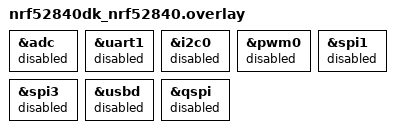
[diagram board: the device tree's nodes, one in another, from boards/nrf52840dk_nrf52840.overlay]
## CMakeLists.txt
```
cmake_minimum_required(VERSION 3.20.0)

find_package(Zephyr HINTS $ENV{ZEPHYR_BASE})
project(matter_nrf52840_thread)

include(${ZEPHYR_CONNECTEDHOMEIP_MODULE_DIR}/config/nrfconnect/app/enable-gnu-std.cmake)
include(${ZEPHYR_NRF_MODULE_DIR}/samples/matter/common/cmake/source_common.cmake)
include(${ZEPHYR_NRF_MODULE_DIR}/samples/matter/common/cmake/data_model.cmake)
include(${ZEPHYR_NRF_MODULE_DIR}/samples/matter/common/cmake/zap_helpers.cmake)
ncs_get_zap_parent_dir(ZAP_PARENT_DIR)

target_include_directories(app PRIVATE
    src
    include
    ${ZAP_PARENT_DIR}
)

target_sources(app PRIVATE
    src/main.cpp
    src/app_task.cpp
    src/dynamic/DynamicEndpointManager.cpp
    src/dynamic/DynamicExports.c
    src/llext/ExtensionLoaderCluster.cpp
    src/llext/ExtensionStore.cpp
)

ncs_configure_data_model()

# LLEXT's table of exported syscalls declares every syscall's implementation as
# a variable, which LTO refuses to merge with the real functions ("redeclared as
# variable"). Zephyr has no option for this, so build these two without LTO.
set_source_files_properties(${ZEPHYR_BASE}/subsys/llext/llext_export.c
    TARGET_DIRECTORY subsys__llext
    PROPERTIES COMPILE_OPTIONS $<TARGET_PROPERTY:compiler,prohibit_lto>
)
set_source_files_properties(${ZEPHYR_BINARY_DIR}/syscall_weakdefs_llext.c
    TARGET_DIRECTORY syscall_weakdefs
    PROPERTIES COMPILE_OPTIONS $<TARGET_PROPERTY:compiler,prohibit_lto>
)
```

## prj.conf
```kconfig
CONFIG_CHIP=y
CONFIG_CHIP_PROJECT_CONFIG="src/chip_project_config.h"
CONFIG_CHIP_DEVICE_PRODUCT_NAME="Matter LLEXT"
CONFIG_CHIP_DEVICE_PRODUCT_ID=32773
CONFIG_NCS_SAMPLE_MATTER_ZAP_FILE_PATH="${APPLICATION_CONFIG_DIR}/src/default_zap/bridge.zap"
CONFIG_STD_CPP17=y

CONFIG_CHIP_ENABLE_PAIRING_AUTOSTART=y
CONFIG_CHIP_BLE_EXT_ADVERTISING=y
CONFIG_CHIP_BLE_ADVERTISING_DURATION=60
CONFIG_BT_DEVICE_NAME="MatterLLEXT"
CONFIG_DK_LIBRARY=y

# Flash space comes first here. Same as the release configuration of Nordic's
# Matter samples, and without the bootloader, OTA and factory data as well:
# the device uses the SDK's test DAC and the default test pairing code.
CONFIG_LTO=y
CONFIG_ISR_TABLES_LOCAL_DECLARATION=y
CONFIG_USE_SEGGER_RTT=n
CONFIG_SHELL=n
CONFIG_OPENTHREAD_SHELL=n
CONFIG_CHIP_LIB_SHELL=n
CONFIG_CONSOLE=n
CONFIG_UART_CONSOLE=n
CONFIG_SERIAL=n
CONFIG_LOG=n
CONFIG_LOG_MODE_MINIMAL=n
CONFIG_ASSERT_VERBOSE=n
CONFIG_ASSERT_NO_FILE_INFO=y
CONFIG_PRINTK=n
CONFIG_PRINTK_SYNC=n
CONFIG_THREAD_NAME=n
CONFIG_BOOT_BANNER=n
CONFIG_RESET_ON_FATAL_ERROR=y
CONFIG_CHIP_NFC_ONBOARDING_PAYLOAD=n
CONFIG_CHIP_FACTORY_DATA=n
CONFIG_CHIP_BOOTLOADER_NONE=y
CONFIG_CHIP_DFU_OVER_BT_SMP=n

# The default 8 KiB runs out once a second fabric is added (PSA error -142 while
# committing it). 32 KiB is what Nordic's static partition maps use.
CONFIG_PM_PARTITION_SIZE_SETTINGS_STORAGE=0x8000

# LLEXT: extensions run from RAM, which the MPU's default regions don't allow.
CONFIG_ARM_MPU=n
CONFIG_LLEXT=y
CONFIG_LLEXT_STORAGE_WRITABLE=y
CONFIG_LLEXT_HEAP_SIZE=16
CONFIG_LLEXT_IMPORT_ALL_GLOBALS=y

# The RAM extensions arrive in, via k_malloc(): see
# ExtensionLoaderCluster::kMaxExtensionSize.
CONFIG_HEAP_MEM_POOL_SIZE=12288
# The bridged endpoints' Ember tables live on this heap.
CONFIG_CHIP_MALLOC_SYS_HEAP_SIZE=16384
```

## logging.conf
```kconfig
# Opt-in: console and logging on UART0, for bring-up. Not part of the
# flash-optimized default.
CONFIG_SERIAL=y
CONFIG_CONSOLE=y
CONFIG_UART_CONSOLE=y
CONFIG_PRINTK=y
CONFIG_LOG=y
CONFIG_LOG_MODE_MINIMAL=n
CONFIG_BOOT_BANNER=y
CONFIG_THREAD_NAME=y
CONFIG_RESET_ON_FATAL_ERROR=n
```

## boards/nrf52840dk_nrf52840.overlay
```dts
/* Unused here, to reduce power consumption. */
&adc {
	status = "disabled";
};
&uart1 {
	status = "disabled";
};
&i2c0 {
	status = "disabled";
};
&pwm0 {
	status = "disabled";
};
&spi1 {
	status = "disabled";
};
&spi3 {
	status = "disabled";
};
&usbd {
	status = "disabled";
};
&qspi {
	status = "disabled";
};
```

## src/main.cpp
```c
#include "app_task.h"

#include <zephyr/logging/log.h>

LOG_MODULE_REGISTER(app, CONFIG_CHIP_APP_LOG_LEVEL);

int main()
{
    CHIP_ERROR err = AppTask::Instance().StartApp();

    LOG_ERR("Exited with code %" CHIP_ERROR_FORMAT, err.Format());
    return err == CHIP_NO_ERROR ? EXIT_SUCCESS : EXIT_FAILURE;
}
```

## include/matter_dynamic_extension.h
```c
/*
 * Contract between the 4_llext_dynamic app and an extension loaded through
 * the ExtensionLoaderCluster: how an extension adds Matter endpoints --
 * with their clusters, attributes and command handlers -- to the running
 * device.
 *
 * The app is a Matter bridge (Aggregator on endpoint 1); every endpoint an
 * extension adds shows up as a bridged device below it, the same way
 * connectedhomeip's examples/bridge-app and nRF Connect's bridge sample
 * expose theirs. The difference is that the "bridged device" implementations
 * are not compiled into the app but arrive at runtime as extensions.
 *
 * An extension describes an endpoint with the const tables below and calls
 * matter_dyn_endpoint_add() from its run() function. From then on the app
 * calls back into the extension whenever a controller reads or writes one of
 * the declared attributes or invokes one of the declared commands.
 *
 * Symbols an extension exports (LL_EXTENSION_SYMBOL), all optional:
 *
 *   void run(void);   called once, right after loading
 *   void poll(void);  called about once per second while loaded
 *
 * Everything the app calls -- run(), poll() and the three cluster callbacks
 * -- runs on the Matter thread, one call at a time, and the functions
 * declared at the bottom of this header may only be called from inside those
 * calls (adding and removing endpoints only from run() and poll()). An
 * extension therefore needs no locking, and must not block.
 *
 * When an extension is unloaded, the app removes all endpoints it added;
 * there is no cleanup hook. The tables passed to matter_dyn_endpoint_add()
 * (and everything they point to) must stay valid for as long as the
 * extension is loaded -- make them static.
 */

#ifndef MATTER_DYNAMIC_EXTENSION_H_
#define MATTER_DYNAMIC_EXTENSION_H_

#include <stdbool.h>
#include <stdint.h>

#ifdef __cplusplus
extern "C" {
#endif

/* Attribute data types. Values travel as fixed-size little-endian buffers. */
enum matter_dyn_type {
	MATTER_DYN_BOOL,     /* 1 byte */
	MATTER_DYN_UINT8,    /* 1 byte */
	MATTER_DYN_UINT16,   /* 2 bytes */
	MATTER_DYN_UINT32,   /* 4 bytes */
	MATTER_DYN_INT8,     /* 1 byte */
	MATTER_DYN_INT16,    /* 2 bytes */
	MATTER_DYN_INT32,    /* 4 bytes */
	MATTER_DYN_ENUM8,    /* 1 byte */
	MATTER_DYN_BITMAP8,  /* 1 byte */
	MATTER_DYN_BITMAP32, /* 4 bytes */
};

/* Attribute flags. */
#define MATTER_DYN_WRITABLE 0x01
/*
 * A nullable attribute reports null by returning its type's reserved value:
 * 0xFF.. for unsigned types, the most negative value for signed ones (e.g.
 * INT16_MIN), 0xFF for bool/enum8.
 */
#define MATTER_DYN_NULLABLE 0x02

struct matter_dyn_attribute {
	uint32_t id;
	uint8_t type;  /* enum matter_dyn_type */
	uint8_t flags; /* MATTER_DYN_WRITABLE | MATTER_DYN_NULLABLE */
};

/* One field of an invoked command, as decoded by the app. */
enum matter_dyn_arg_type {
	MATTER_DYN_ARG_NULL,
	MATTER_DYN_ARG_BOOL,
	MATTER_DYN_ARG_UINT,
	MATTER_DYN_ARG_INT,
};

struct matter_dyn_arg {
	uint8_t tag;  /* the field's context tag, i.e. its field ID */
	uint8_t type; /* enum matter_dyn_arg_type */
	int64_t value;
};

/* At most this many fields of a command are passed on; the rest is dropped. */
#define MATTER_DYN_MAX_ARGS 8

/*
 * Callback results: 0 for success; a positive value is sent to the controller
 * as that Interaction Model status code (e.g. 0x87 ConstraintError); any
 * negative value becomes a generic Failure.
 */

/* Write the attribute's current value to buf (len is its type's size). */
typedef int (*matter_dyn_read_fn)(uint16_t endpoint, uint32_t cluster, uint32_t attribute,
				  uint8_t *buf, uint16_t len);

/* A controller (or one of the app's own cluster servers) set a new value. */
typedef int (*matter_dyn_write_fn)(uint16_t endpoint, uint32_t cluster, uint32_t attribute,
				   const uint8_t *buf, uint16_t len);

/* A controller invoked one of the cluster's commands. */
typedef int (*matter_dyn_invoke_fn)(uint16_t endpoint, uint32_t cluster, uint32_t command,
				    const struct matter_dyn_arg *args, uint8_t arg_count);

struct matter_dyn_cluster {
	uint32_t id;
	/* The global ClusterRevision and FeatureMap attributes; served by the
	 * app, don't list them in `attributes`.
	 */
	uint16_t revision;
	uint32_t feature_map;

	const struct matter_dyn_attribute *attributes;
	uint8_t attribute_count;

	/* IDs of the commands the cluster accepts. */
	const uint32_t *commands;
	uint8_t command_count;

	matter_dyn_read_fn read;
	matter_dyn_write_fn write; /* may be NULL if nothing is writable */
	/*
	 * NULL: commands go to the app's built-in server for this cluster,
	 * if it has one. That is the case for On/Off, whose server turns
	 * On/Off/Toggle into a write of the OnOff attribute -- so an on/off
	 * light only needs read and write. Set it to handle the commands in
	 * the extension instead, which is the only option for clusters the
	 * app knows nothing about.
	 */
	matter_dyn_invoke_fn invoke;
};

struct matter_dyn_endpoint {
	/* Matter device type, e.g. 0x0100 (On/Off Light), and its revision. */
	uint32_t device_type;
	uint8_t device_type_revision;
	/* NodeLabel of the bridged device, at most 32 characters. */
	const char *name;

	const struct matter_dyn_cluster *clusters;
	uint8_t cluster_count;
};

/*
 * Adds an endpoint. Only from run() or poll(). Returns its endpoint ID
 * (> 0), or a negative errno: -EINVAL for a malformed description or a call
 * from elsewhere, -ENOMEM, or -ENOSPC if all dynamic endpoints are in use.
 */
int matter_dyn_endpoint_add(const struct matter_dyn_endpoint *endpoint);

/*
 * Removes an endpoint this extension added. Only from run() or poll().
 * Optional -- unloading the extension removes them all. Returns 0 or -ENOENT.
 */
int matter_dyn_endpoint_remove(uint16_t endpoint);

/*
 * Tells the app that an attribute's value changed on the extension's own
 * initiative, so that subscribed controllers get a report. Not needed for
 * changes made through the write callback.
 */
void matter_dyn_attribute_changed(uint16_t endpoint, uint32_t cluster, uint32_t attribute);

#ifdef __cplusplus
}
#endif

#endif /* MATTER_DYNAMIC_EXTENSION_H_ */
```

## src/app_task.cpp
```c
#include "app_task.h"

#include "app/matter_init.h"
#include "app/task_executor.h"
#include "board/board.h"
#include "dynamic/DynamicEndpointManager.h"
#include "llext/ExtensionLoaderCluster.h"

#include <app/server-cluster/ServerClusterInterfaceRegistry.h>
#include <data-model-providers/codegen/CodegenDataModelProvider.h>

#include <zephyr/logging/log.h>

LOG_MODULE_DECLARE(app, CONFIG_CHIP_APP_LOG_LEVEL);

using namespace chip;
using namespace chip::app;

namespace {

CHIP_ERROR PostServerInit()
{
    DynamicEndpointManager::Init();

    static RegisteredServerCluster<ExtensionLoaderCluster> sExtensionLoaderCluster;
    ReturnErrorOnFailure(CodegenDataModelProvider::Instance().Registry().Register(sExtensionLoaderCluster.Registration()));

    // Not right here: Nordic's init enables the watchdog after this callback,
    // and a stored extension that hangs has to run into it. This runs next on
    // the Matter thread, about a second after boot, ahead of controllers
    // reconnecting, so in practice they don't see the endpoints missing.
    return DeviceLayer::PlatformMgr().ScheduleWork(
        [](intptr_t cluster) { reinterpret_cast<ExtensionLoaderCluster *>(cluster)->RestoreExtensions(); },
        reinterpret_cast<intptr_t>(&sExtensionLoaderCluster.Cluster()));
}

} // namespace

CHIP_ERROR AppTask::Init()
{
    ReturnErrorOnFailure(Nrf::Matter::PrepareServer(Nrf::Matter::InitData{ .mPostServerInitClbk = PostServerInit }));

    if (!Nrf::GetBoard().Init())
    {
        LOG_ERR("User interface initialization failed.");
        return CHIP_ERROR_INCORRECT_STATE;
    }

    ReturnErrorOnFailure(Nrf::Matter::RegisterEventHandler(Nrf::Board::DefaultMatterEventHandler, 0));

    return Nrf::Matter::StartServer();
}

CHIP_ERROR AppTask::StartApp()
{
    ReturnErrorOnFailure(Init());

    while (true)
    {
        Nrf::DispatchNextTask();
    }

    return CHIP_NO_ERROR;
}
```
